# GD32H75E register map
File version: 1.0
CPU: CM7 r1p2, little endian, MPU, FPU, 4 interrupt priority bits
Registers are 32-bit, read-write, reset 0x0 unless marked. A register's access mark holds for its fields unless they carry their own. Offsets are from the block's base; [hi:lo] are bit positions; {n}, {i} and the like mark numbered series; 'fields as' and 'values as' point back to an identical list.

## TRIGSEL — Trigger selection controller
Base 0x40018400
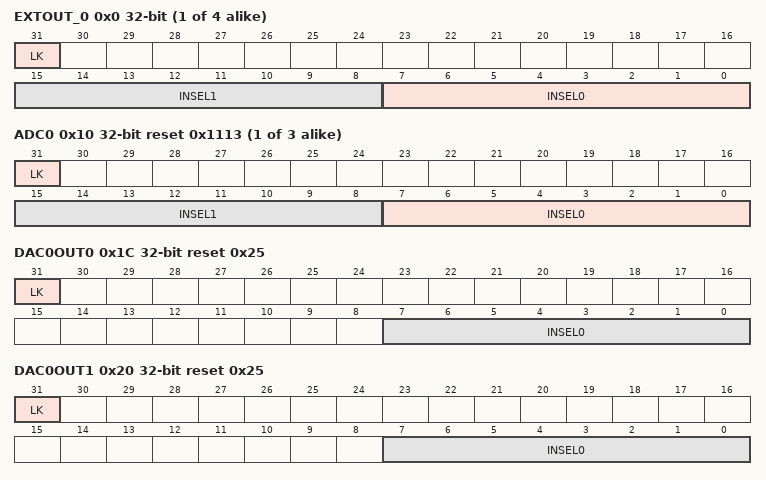
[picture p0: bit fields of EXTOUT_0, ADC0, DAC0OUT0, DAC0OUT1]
{0x0+4i} EXTOUT_{i} (i=0..3) — Trigger selection for EXTOUT register {i}
  [31] LK — TRIGSEL register lock.
  [15:8] INSEL1 — Trigger input source selection for output1
  [7:0] INSEL0 — Trigger input source selection for output0
{0x10+4i} ADC{i} reset 0x1113 (i=0..2) — Trigger selection for ADC{i} register
  fields as EXTOUT_0
0x1C DAC0OUT0 reset 0x25 — Trigger selection for DAC0_OUT0 register
  [31] LK — TRIGSEL register lock.
  [7:0] INSEL0 — Trigger input source selection for output0
0x20 DAC0OUT1 reset 0x25 — Trigger selection for DAC0_OUT1 register
  fields as DAC0OUT0
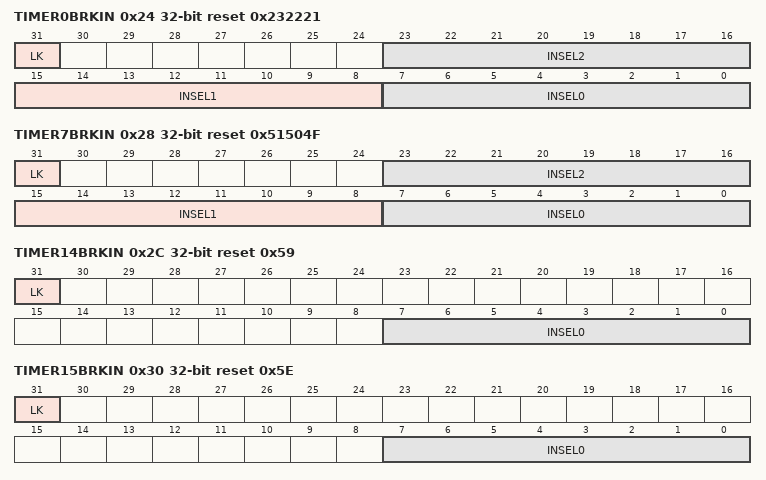
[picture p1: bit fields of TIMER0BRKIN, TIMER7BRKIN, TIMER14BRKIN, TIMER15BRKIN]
0x24 TIMER0BRKIN reset 0x232221 — Trigger selection for TIMER0_BRKIN register
  [31] LK — TRIGSEL register lock.
  [23:16] INSEL2 — Trigger input source selection for output2
  [15:8] INSEL1 — Trigger input source selection for output1
  [7:0] INSEL0 — Trigger input source selection for output0
0x28 TIMER7BRKIN reset 0x51504F — Trigger selection for TIMER7_BRKIN register
  fields as TIMER0BRKIN
0x2C TIMER14BRKIN reset 0x59 — Trigger selection for TIMER14_BRKIN register
  fields as DAC0OUT0
0x30 TIMER15BRKIN reset 0x5E — Trigger selection for TIMER15_BRKIN register
  fields as DAC0OUT0
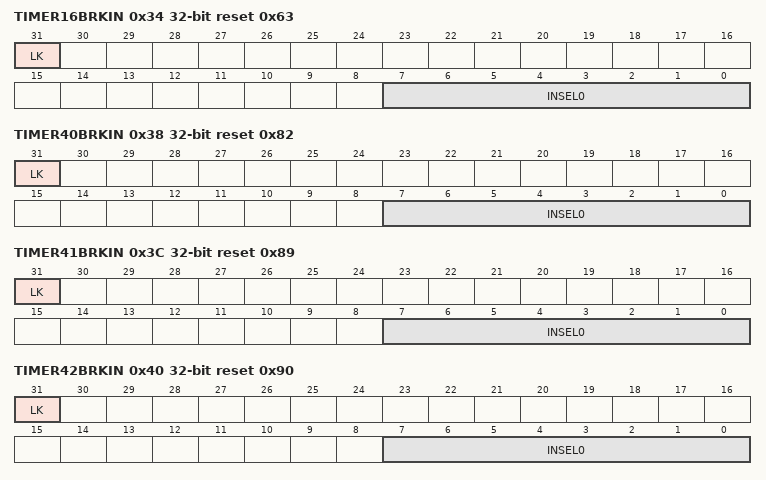
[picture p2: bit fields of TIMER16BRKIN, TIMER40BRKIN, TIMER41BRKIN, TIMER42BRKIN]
0x34 TIMER16BRKIN reset 0x63 — Trigger selection for TIMER16_BRKIN register
  fields as DAC0OUT0
0x38 TIMER40BRKIN reset 0x82 — Trigger selection for TIMER40_BRKIN register
  fields as DAC0OUT0
0x3C TIMER41BRKIN reset 0x89 — Trigger selection for TIMER41_BRKIN register
  fields as DAC0OUT0
0x40 TIMER42BRKIN reset 0x90 — Trigger selection for TIMER42_BRKIN register
  fields as DAC0OUT0
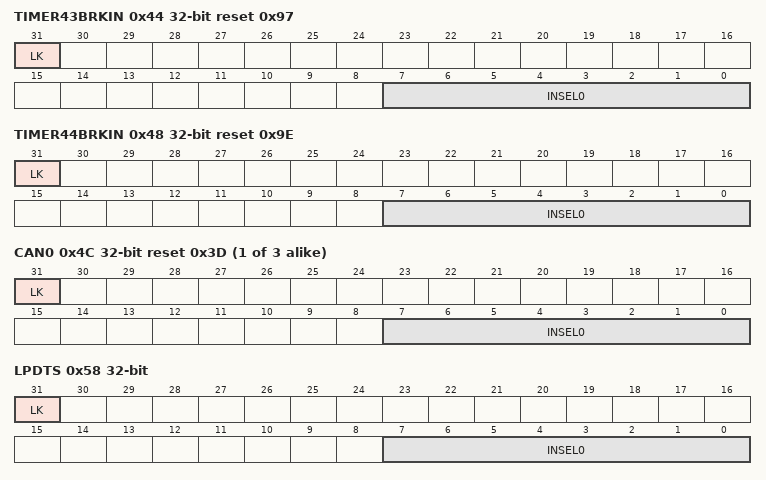
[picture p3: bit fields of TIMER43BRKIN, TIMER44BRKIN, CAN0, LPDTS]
0x44 TIMER43BRKIN reset 0x97 — Trigger selection for TIMER43_BRKIN register
  fields as DAC0OUT0
0x48 TIMER44BRKIN reset 0x9E — Trigger selection for TIMER44_BRKIN register
  fields as DAC0OUT0
{0x4C+4i} CAN{i} reset 0x3D (i=0..2) — Trigger selection for CAN{i} register
  fields as DAC0OUT0
0x58 LPDTS — Trigger selection for LPDTS register
  fields as DAC0OUT0
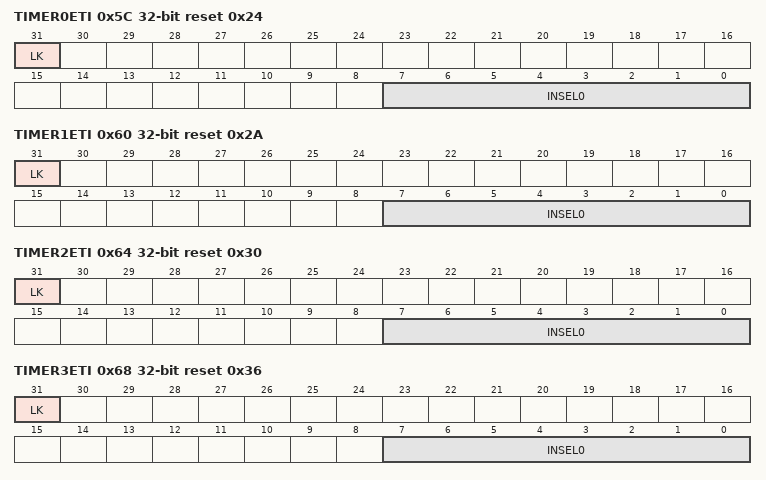
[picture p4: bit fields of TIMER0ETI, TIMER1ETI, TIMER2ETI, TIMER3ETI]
0x5C TIMER0ETI reset 0x24 — Trigger selection for TIMER0_ETI register
  fields as DAC0OUT0
0x60 TIMER1ETI reset 0x2A — Trigger selection for TIMER1_ETI register
  fields as DAC0OUT0
0x64 TIMER2ETI reset 0x30 — Trigger selection for TIMER2_ETI register
  fields as DAC0OUT0
0x68 TIMER3ETI reset 0x36 — Trigger selection for TIMER3_ETI register
  fields as DAC0OUT0
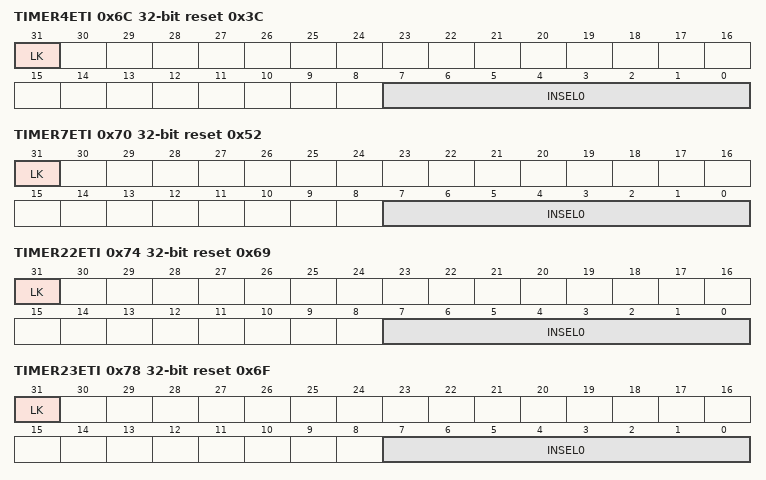
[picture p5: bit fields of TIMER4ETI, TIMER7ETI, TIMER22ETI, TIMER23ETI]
0x6C TIMER4ETI reset 0x3C — Trigger selection for TIMER4_ETI register
  fields as DAC0OUT0
0x70 TIMER7ETI reset 0x52 — Trigger selection for TIMER7_ETI register
  fields as DAC0OUT0
0x74 TIMER22ETI reset 0x69 — Trigger selection for TIMER22_ETI register
  fields as DAC0OUT0
0x78 TIMER23ETI reset 0x6F — Trigger selection for TIMER23_ETI register
  fields as DAC0OUT0
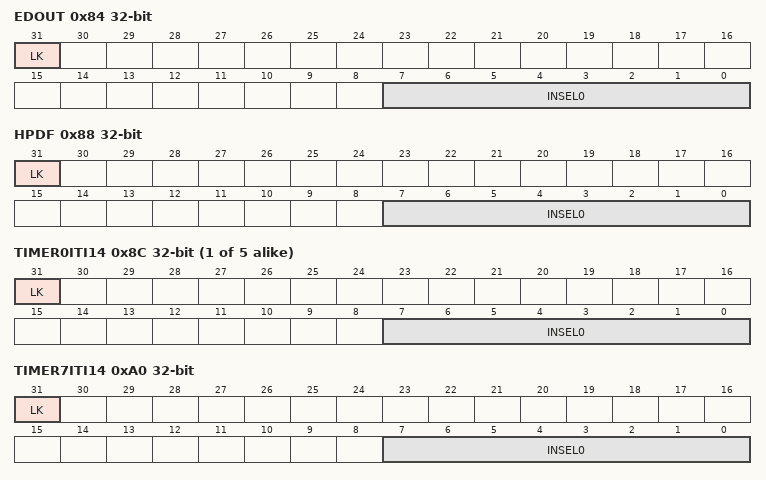
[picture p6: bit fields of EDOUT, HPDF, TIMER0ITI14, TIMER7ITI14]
0x84 EDOUT — Trigger selection for EDOUT register
  fields as DAC0OUT0
0x88 HPDF — Trigger selection for HPDF register
  fields as DAC0OUT0
{0x8C+4i} TIMER{i}ITI14 (i=0..4) — Trigger selection for TIMER{i}_ITI14 register
  fields as DAC0OUT0
0xA0 TIMER7ITI14 — Trigger selection for TIMER7_ITI14 register
  fields as DAC0OUT0
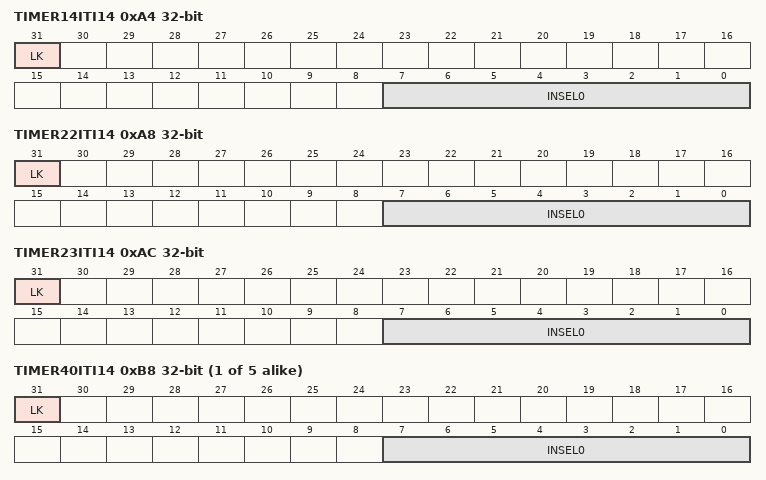
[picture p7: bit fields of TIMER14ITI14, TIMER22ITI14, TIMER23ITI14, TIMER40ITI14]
0xA4 TIMER14ITI14 — Trigger selection for TIMER14_ITI14 register
  fields as DAC0OUT0
0xA8 TIMER22ITI14 — Trigger selection for TIMER22_ITI14 register
  fields as DAC0OUT0
0xAC TIMER23ITI14 — Trigger selection for TIMER23_ITI14 register
  fields as DAC0OUT0
{0x18+4i} TIMER{i}ITI14 (i=40..44) — Trigger selection for TIMER{i}_ITI14 register
  fields as DAC0OUT0

## TRNG — True random number generator
Base 0x48021800
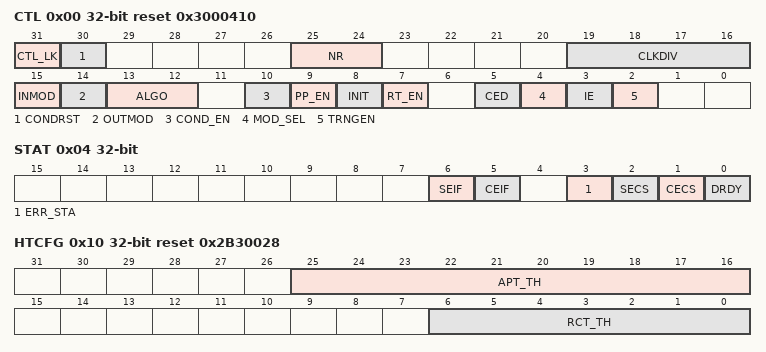
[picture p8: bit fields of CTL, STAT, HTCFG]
0x00 CTL access per field reset 0x3000410 — Control register
  [31] CTL_LK ro — TRNG_CTL register lock bit
  [30] CONDRST rw — reset conditioning logic
  [25:24] NR rw — analog trng power mode
  [19:16] CLKDIV rw — TRNG clock divider
  [15] INMOD rw — select random seed number input to conditioning module
  [14] OUTMOD rw — select random data width output of conditioning module
  [13:12] ALGO rw — None NIST compliant
  [10] COND_EN rw — enable conditioning component
  [9] PP_EN rw — enable post_processing
  [8] INIT rw — init hash algo when conditioning enabled
  [7] RT_EN rw — replace test enable bit
  [5] CED rw — clock error detection
  [4] MOD_SEL rw — LFSR or NIST mode selection
  [3] IE rw — Interrupt enabled bit
  [2] TRNGEN rw — TRNG enabled bit
0x04 STAT access per field — Status register
  [6] SEIF rw — Seed error interrupt flag
  [5] CEIF rw — Clock error interrupt flag
  [3] ERR_STA rw — NIST mode error flag, this bit could be reset by CONDRST
  [2] SECS ro — Seed error current status
  [1] CECS ro — Clock error current status
  [0] DRDY ro — Random data ready status bit
0x08 DATA ro
  [31:0] TRNDATA — 32-bit random data
0x10 HTCFG reset 0x2B30028 — Health tests configure register
  [25:16] APT_TH — Adaptive proportion test threshold
  [6:0] RCT_TH — Repetition count test threshold
